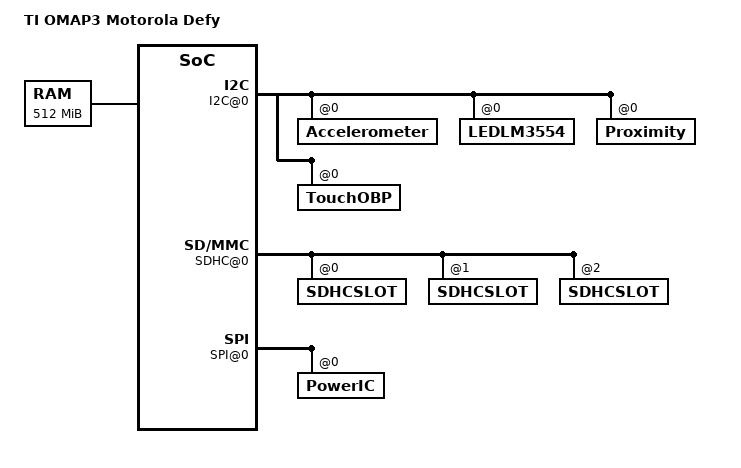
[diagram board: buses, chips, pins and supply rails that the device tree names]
/* Motorola Defy - production version */

/dts-v1/;
/include/ "omap36xx.dtsi"
/ {

	model = "TI OMAP3 Motorola Defy";
	compatible = "ti,mapphone";

	memory {
		device_type = "memory";
		reg = <0x80000000 0x20000000>; /* 512 MB */
	};

	Aliases@0 {
	};

	Chosen@0 {
		bp_model = "UMTS";
		formfactor = <0x3>;
		last_compat_version = <0x132b7fc>;
		omap3630_rev = <0x36301000>;
		product = <0x1230>;
		usb_id_prod_name = "MB526";
		version = <0x132b7fc>;
	};

	Machine@0 {
		cpu_tier = "10";
	};

	System@0 {

		Display@0 {
			byte_pp = [03];
			class = "Display";
			disp_hw_type = [04];
			disp_intf = [04];
			dispc_timing_hbp = [02 00];
			dispc_timing_hfp = [00 00];
			dispc_timing_hsw = [02 00];
			dispc_timing_vbp = [01 00];
			dispc_timing_vfp = [00 00];
			dispc_timing_vsw = [01 00];
			dsi_clk_lane = [01];
			dsi_clk_pol = [00];
			dsi_data1_lane = [02];
			dsi_data1_pol = [00];
			dsi_data2_lane = [03];
			dsi_data2_pol = [00];
			gpio_reset = <0x88000000>;
			height = [56 03];
			lck_div = [01 00];
			lp_clk_div = [07 00];
			pck_div = [05 00];
			phy_height_mm = [52 00];
			phy_width_mm = [2e 00];
			pixel_fmt = <0x05000000>;
			regm = [ad 00];
			regm3 = [05 00];
			regm4 = [05 00];
			regn = [0d 00];
			type = <0x001a0001>;
			width = [e0 01];
		};

		Display@1 {
			class = "Display";
			gpio_int = <0x19000000>;
			gpio_mux_en = <0x45000000>;
			gpio_mux_select = <0x07000000>;
			gpio_pwr_en = <0x1a000000>;
			type = <0x19000000>;
		};

		DisplayBacklight@0 {
			class = "DisplayBacklight";
			ruth_lcd = [00];
			tablet_lcd = [01];
			type = <0x0d000000>;
		};

		Feature@0 {
			class = "Feature";
			feature_cam_flags = [01];
			feature_cam_regulators = "vcam";
			feature_hdmi = [01];
			feature_mipi_cam = [00];
			feature_no_nand = [01];
			feature_smart_cam = [00];
			type = <0x0f000000>;
		};

		GPIO@0 {
			class = "GPIO";
			signalmap = <	0x08000000 0x62745F77 0x616B655F 0x62000000 0x20202020 0x202020 /* pin = 8, name = bt_wake_b		*/
					0x16000000 0x61636365 0x6c315f69 0x6e740000 0x20202020 0x202020 /* pin = 22, name = accel1_int		*/
					0x17000000 0x6770735f 0x7374616e 0x64627900 0x20202020 0x202020 /* pin = 23, name = gps_standby		*/
					0x1c000000 0x616b6d38 0x3937335f 0x72657365 0x74000000 0x202020 /* pin = 28, name = akm8973_reset	*/
					0x3b000000 0x6770735f 0x72657365 0x74000000 0x20202020 0x202020 /* pin = 59, name = gps_reset		*/
					0x41000000 0x776c616e 0x5f686f73 0x745f7761 0x6b650000 0x202020 /* pin = 65, name = wlan_host_wake	*/
					0x10000000 0x616c735f 0x696e7400 0x20202020 0x20202020 0x202020 /* pin = 16, name = als_int		*/
					0x63000000 0x746f7563 0x685f7061 0x6e656c5f 0x696e7400 0x202020 /* pin = 99, name = touch_panel_int	*/
					0xa0000000 0x6770735f 0x696e7465 0x72727570 0x74000000 0x202020 /* pin = 160, name = gps_interrupt	*/
					0xa4000000 0x746f7563 0x685f7061 0x6e656c5f 0x72737400 0x202020 /* pin = 164, name = touch_panel_rst	*/
					0xaf000000 0x616b6d38 0x3937335f 0x696e7400 0x20202020 0x202020 /* pin = 175, name = akm8973_int	*/
					0xb0000000 0x706f7765 0x725f6f66 0x66000000 0x20202020 0x202020 /* pin = 176, name = power_off		*/
					0xf0000000 0x62745f68 0x6f73745f 0x77616b65 0x5f620000 0x202020 /* pin = 15, name = bt_host_wake_b	*/
					0x15000000 0x62745f72 0x65736574 0x5f620000 0x20202020 0x202020 /* pin = 21, name = bt_reset_b 		*/
					0xb6000000 0x7669625f 0x636f6e74 0x726f6c5f 0x656e0000 0x202020 /* pin = 182, name = vib_control_en 	*/
					0xba000000 0x776c616e 0x5f726573 0x65740000 0x20202020 0x202020 /* pin = 186, name = wlan_reset 	*/
					0x5c000000 0x6c6d3335 0x33305f69 0x6e740000 0x20202020 0x202020 /* pin = 92, name = lm3530_int 		*/
					0x5d000000 0x6c63645f 0x70616e65 0x6c5f7265 0x73657400 0x202020 /* pin = 93, name = lcd_panel_reset 	*/
					0x5d000000 0x6c6d3335 0x33305f72 0x65736574 0x20202020 0x202020 /* pin = 93, name = lm3530_reset 	*/
					0x5c000000 0x6c63645f 0x70616e65 0x6c5f7364 0x20202020 0x202020 /* pin = 92, name = lcd_panel_sd	*/
					0x62000000 0x6770696f 0x5f63616d 0x5f726573 0x65740000 0x202020 /* pin = 98, name = gpio_cam_reset 	*/
					0x40000000 0x6770696f 0x5f63616d 0x5f707764 0x6e000000 0x202020	/* pin = 64, name = gpio_cam_pwdn	*/
					>;
			type = <0x03000300>;

			HallEffect@0 {
				class = "HallEffect";
				device_available = [01];
				type = <0x17000000>;
			};
		};

		GPIODev@0 {
			class = "GPIODev";
			init = <0x3b 0x5f737067 0x65736572 0x20202074 0x20202020 0x202020 0x8 0x17 0x5f737067 0x6e617473 0x20796264 0x20202020 0x202020 0x8 0xa0 0x5f737067 0x65746e69 0x70757272 0x20202074 0x202020 0x102 0x15 0x725f7462 0x74657365 0x2020625f 0x20202020 0x202020 0x8 0x8 0x775f7462 0x5f656b61 0x20202062 0x20202020 0x202020 0x8 0x5d 0x5f64636c 0x656e6170 0x65725f6c 0x20746573 0x202020 0x4 0x5d 0x35336d6c 0x725f3033 0x74657365 0x20202020 0x202020 0x4>;
			type = <0x03000a00>;
		};

		I2C@0 {
			bus1devices = "qtouch-obp-ts,lm3530_led,isl29030_als_ir";
			bus2devices = "akm8973,lis331dlh,kxtf9";
			bus3devices = "camise,HP_GEN_LENS,lm3554_led,mt9p012";
			class = "I2C";
			type = <0x01000300>;

			Accelerometer@0 {
				axis_map_x = [00];
				axis_map_y = [01];
				axis_map_z = [02];
				class = "Accelerometer";
				negate_x = [01];
				negate_y = [00];
				negate_z = [01];
				type = <0x18000000>;
			};

			LEDLM3554@0 {
				class = "LEDLM3554";
				device_available = <0x01000000>;
				flash_duration_def = [cf];
				type = <0x0b000100>;
			};

			Proximity@0 {
				class = "Proximity";
				configure = [62];
				crosstalk_vs_covered_threshold = [50];
				default_prox_noise_floor = [50];
				i2c_addr = [44];
				interrupt_cntrl = [20];
				lens_percent_t = [14];
				num_samples_for_noise_floor = [05];
				prox_higher_threshold = [14];
				prox_lower_threshold = [0a];
				type = <0x1d000000>;
			};

			TouchOBP@0 {
				abs_max_w = <0x14000000>;
				abs_max_x = <0x03eb0000>;
				abs_max_y = <0x03ad0000>;
				abs_min_x = <0x15000000>;
				abs_min_y = <0x00000000>;
				boot_i2c_address = [24];
				class = "TouchOBP";
				i2c,address = <0x4a000000>;
				obj_t15 = [01 00 09 01 03 00 00 ff 01 00];
				obj_t19 = <0x3c000100 0x00000000 0x00000000 0x00000000>;
				obj_t22 = [25 00 00 19 00 e7 ff 04 14 00 00 00 07 0e 14 16 04];
				obj_t28 = [00 00 02 04 08 07];
				obj_t7 = [0a 11 00];
				obj_t8 = <0x140a000a 0x01006400>;
				obj_t9 = [0b 00 00 12 09 00 10 28 02 00 19 14 05 3e 02 20 38 05 00 00 00 00 04 00 17 21 d8 30 87 91 00];
				touch_key_map = <0x8b000000 0x29000000 0x03810000 0x59000000 0x42000000 0x66000000 0xac000000 0x038100000 0x64000000 0x42000000 0x9e000000 0x013400000 0x038100000 0x64000000 0x42000000 0xd9000000 0x01ba00000 0x038100000 0x5e000000 0x42000000>;
				touchobp-flags = <0x7c000000>;
				type = <0x07000600>;
				x_delta = <0x04000000>;
				y_delta = <0x04000000>;
			};
		};

		IOMUX@0 {
			class = "IOMUX";
			offmodeinit = [30 00 00 01 00 00 7a 00 00 01 00 01 7c 00 00 01 00 01 7e 00 00 01 00 01 80 00 00 01 00 01 82 00 01 01 00 01 84 00 00 01 00 01 86 00 00 01 00 01 88 00 00 01 00 01 d2 01 00 01 00 00 16 01 00 01 00 01 18 01 00 01 00 01 2e 01 00 01 00 01 d6 01 00 01 00 01 da 01 00 01 00 01];
			offmodewkupsinit = [1a 0a 01 01 00 00];
			padinit = <0x107007a 0x7007c03 0x7e0301 0x80030107 0x3010400 0x1070082 0x4008403 0x860301 0x88030107 0x3010700 0x107008a 0x4008c03 0xb20301 0xb4030107 0x3010700 0x10700b6 0x700b803 0xba0301 0xbc030107 0x3010700 0x400be 0x700ce00 0xd00301 0xd2010004 0x3010400 0x10700d4 0x700d603 0xd80301 0xda030107 0x3010700 0x10700e8 0x700ea03 0xec0301 0xee030107 0x3010700 0x10700f0 0x700f203 0xf40301 0xf6030107 0x3010700 0x10700f8 0x700fa03 0xfc0301 0xfe030107 0x3010700 0x1070100 0x7010203 0x1040301 0x6030107 0x3010701 0x1040108 0x4010a00 0x10c0000 0xe000100 0x10001 0x1000110 0x11200 0x1140001 0x16000004 0x10401 0x1070118 0x11a03 0x11c0001 0x1e000100 0x10001 0x1000120 0x12200 0x1240001 0x26000100 0x10001 0x1000128 0x12a00 0x12c0001 0x2e000100 0x10401 0x1070130 0x7013203 0x1480301 0x4a030100 0x3010001 0x100014c 0x14e03 0x1500301 0x52030102 0x10201 0x20154 0x2015600 0x1580301 0x5a000100 0x3010001 0x100015c 0x15e03 0x1600301 0x62030100 0x3010001 0x40164 0x5016600 0x1680001 0x6a010105 0x1010501 0x101018e 0x4019400 0x19c0301 0xc8030004 0x3010101 0x10101ca 0x101cc03 0x1ce0301 0xd0030101 0x1010401 0x401d2 0x701d403 0x1d60301 0xd8030100 0x1 0x264 0x1da00 0x1dc0101 0xde000000 0x3010401 0x401e2 0x205d800 0x5da0001 0xdc030102 0x3010705 0x10405de 0x405e000 0x5e20001 0xe4030102 0x3010205 0x10205e6 0x205e803 0x5ea0301 0xec000004 0x10405 0x405ee 0x5f000 0x5f20001 0xf4000100 0x10005 0x10005f6 0x405f800 0x1720000 0x80010105 0x1010501>;
			padwkupsinit = [18 0a 04 00 00 1a 0a 04 01 00 14 0a 04 00 00 16 0a 00 01 03 24 0a 07 00 00 26 0a 01 00 00];
			type = <0x30004>;
		};

		Keypad@0 {
			class = "Keypad";
			columnregister = <0x2b000000>;
			columns = <0x01000000>;
			mapnum = <0x02000000>;
			maps = <0x73007200>;
			dev_name = "umts_jordan-keypad";
			rowregister = <0x25000000 0x27000000>;
			rows = <0x02000000>;
			type = <0x01000000>;
		};

		LEDController@0 {
			class = "LEDController";
			dev_name = "button-backlight";
			type = <0x02100010>;
		};

		LEDController@1 {
			class = "LEDController";
			dev_name_blue = "blue";
			dev_name_green = "green";
			dev_name_red = "red";
			type = <0x02100050>;
		};

		SDHC@0 {
			class = "SDHC";
			type = <0x03000800>;

			SDHCSLOT@0 {
				card_connect = <0x01000000>;
				card_detection = <0x01000000>;
				host_capability = <0x11000000>;
				pwr_supply = <0x01000000>;
			};

			SDHCSLOT@1 {
				card_connect = <0x02000000>;
				card_detection = <0x00000000>;
				host_capability = <0x11100000>;
			};

			SDHCSLOT@2 {
				card_connect = <0x03000000>;
				card_detection = <0x01000000>;
				host_capability = <0x11000000>;
				sdcnum = [03];
			};
		};

		SPI@0 {
			class = "SPI";
			type = <0x03000700>;

			PowerIC@0 {
				bus_num = [02 00];
				class = "PowerIC";
				regulator_init = <0x06000000 0x1b774000 0x1b774000 0x08000000 0x08010001 0x38000000 0x38001c9c 0x01001c9c 0x01000000 0x0d010000 0x57d80000 0x57d8002a 0x09002a00 0x01000000 0x0e010000 0x2a57d800 0x2a57d800 0x09000000 0x01000100 0x0f000000 0x2a57d800 0x2a57d800 0x09000000 0x12010001 0x40000000 0x20001b77 0x09002c40 0x00000000 0x13000000 0x77400000 0x04020001b 0x09002c00 0x00000000 0x05000000 0x2c402000 0x2c402000 0x08000000 0x01000100>;
				regulator_mode = <0x06000000 0x08004300 0x82000000 0xd0000000 0x0e002400 0x01000000 0xf0000000 0x16002300 0x14000000 0xa0000000 0x05001300 0x82000000 >;
				spiinit = <0x2e000000 0xdb040000 0x36000000 0x40340000 0x37000000 0x34340000 0x9c000000 0x00000000>;
				type = <0x03000600>;
			};
		};

		UART@0 {
			class = "UART";
			gps_port = <0x01000000>;
			hw_flow_control = [40 c0 00];
			type = <0x03000b00>;
		};

		VideoOut@0 {
			class = "VideoOut";
			max_buffer_size = <0x1c300000>;
			max_height = [d0 02];
			max_width = [00 05];
			type = <0x0e000000>;
		};
	};
};
